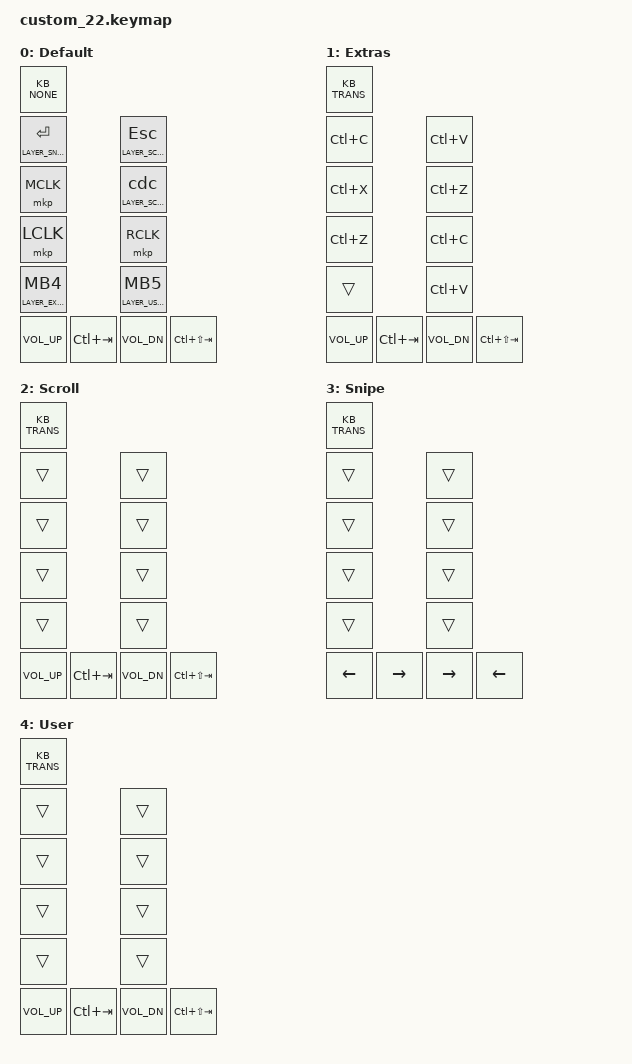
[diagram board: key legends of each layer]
/*
 * Taipo keymap for custom_22 keyboard + endgame trackball on xiao_dongle.
 *
 * Keyboard: positions 0-21 (via rolling combos)
 * Trackball buttons: positions 22-29
 * Trackball encoders: positions 30-33
 *
 * Trackball layers:
 *   0 - Default: mouse buttons, hold-tap for layers
 *   1 - Extras: copy/paste shortcuts
 *   2 - Scroll: trackball becomes scroll wheel
 *   3 - Snipe: slow precision pointer
 *   4 - User: customizable
 */

#include <behaviors.dtsi>
#include <input/processors.dtsi>
#include <dt-bindings/zmk/bt.h>
#include <dt-bindings/zmk/keys.h>
#include <dt-bindings/zmk/outputs.h>
#include <dt-bindings/zmk/pointing.h>
#include <dt-bindings/zmk/matrix_transform.h>
#include <dt-bindings/zmk/input_transform.h>

// CONFIG
#define COMBO_TIMEOUT 200
#define COMBO_LAYERS 0 1 2 3 4
#define STICKY_TIMEOUT 500

// TRACKBALL LAYERS
#define LAYER_DEFAULT      0
#define LAYER_EXTRAS       1
#define LAYER_SCROLL       2
#define LAYER_SNIPE        3
#define LAYER_USER         4

// INPUT PROCESSOR TUNING
#define TWIST_MULTIPLIER   1
#define TWIST_DIVISOR      10
#define SCROLL_MULTIPLIER  1
#define SCROLL_DIVISOR     3
#define SNIPE_MULTIPLIER   1
#define SNIPE_DIVISOR      4

// LEFT SIDE (col 0-10, no offset)
#define TLI 3
#define TLM 2
#define TLR 1
#define TLP 0
#define BLI 11
#define BLM 10
#define BLR 9
#define BLP 8
#define LOT 16
#define LIT 17

// RIGHT SIDE (col 0-10, col-offset=11 -> positions 11-21)
#define TRI 4
#define TRM 5
#define TRR 6
#define TRP 7
#define BRI 12
#define BRM 13
#define BRR 14
#define BRP 15
#define ROT 21
#define RIT 20

// Shorthand for 22 keyboard &none entries (default layer)
#define KB_NONE \
    &none &none &none &none  &none &none &none &none \
    &none &none &none &none  &none &none &none &none \
          &none &none &none  &none &none &none

// Shorthand for 22 keyboard &trans entries (non-default layers)
#define KB_TRANS \
    &trans &trans &trans &trans  &trans &trans &trans &trans \
    &trans &trans &trans &trans  &trans &trans &trans &trans \
           &trans &trans &trans  &trans &trans &trans

&sk {
    release-after-ms = <STICKY_TIMEOUT>;
    quick-release;
};

/*
 * Combined transform: keyboard 22 keys + trackball 12 keys = 34 positions.
 * Overrides the shield's 11-position transform.
 */
&default_transform {
    columns = <34>;
    map = <
        /* Keyboard positions 0-21 */
        RC(0,0)  RC(0,1)  RC(0,2)  RC(0,3)   RC(0,14)  RC(0,13)  RC(0,12)  RC(0,11)
        RC(0,4)  RC(0,5)  RC(0,6)  RC(0,7)   RC(0,18)  RC(0,17)  RC(0,16)  RC(0,15)
                 RC(0,8)  RC(0,9)  RC(0,10)  RC(0,21)  RC(0,20)  RC(0,19)
        /* Trackball positions 22-33 */
        RC(0,22) RC(0,23) RC(0,24) RC(0,25)  RC(0,26)  RC(0,27)
        RC(0,28) RC(0,29) RC(0,30) RC(0,31)  RC(0,32)  RC(0,33)
    >;
};

/ {
  /* Trackball behaviors */
  behaviors {
    ltm: layer-tap-momentary {
      compatible = "zmk,behavior-hold-tap";
      #binding-cells = <2>;
      flavor = "tap-preferred";
      tapping-term-ms = <200>;
      hold-while-undecided;
      bindings = <&mo>, <&mkp>;
    };

    ltmkp: layer-tap-momentary-key-press {
      compatible = "zmk,behavior-hold-tap";
      #binding-cells = <2>;
      flavor = "tap-preferred";
      tapping-term-ms = <200>;
      hold-while-undecided;
      bindings = <&mo>, <&kp>;
    };

    cdch: click-double-click-hold {
      compatible = "zmk,behavior-hold-tap";
      #binding-cells = <2>;
      flavor = "tap-preferred";
      tapping-term-ms = <325>;
      bindings = <&mo>, <&cdc>;
    };

    cdc: click-double-click {
      compatible = "zmk,behavior-tap-dance";
      #binding-cells = <0>;
      tapping-term-ms = <300>;
      bindings = <&kp LC(C)>, <&kp LC(V)>;
    };
  };

  rolling_combos {
    compatible = "zmk,rolling-combos";
    #include "taipo.dtsi"
  };

  keymap {
    compatible = "zmk,keymap";

    default_layer {
      display-name = "Default";
      sensor-bindings = <&inc_dec_kp C_VOL_UP C_VOL_DN &inc_dec_kp C_VOL_UP C_VOL_DN>;
      bindings = <
        KB_NONE
        /* Trackball buttons 22-29 */
        &ltmkp LAYER_SNIPE ENTER  &ltmkp LAYER_SCROLL ESC
        &mkp MCLK                 &cdch LAYER_SCROLL 0
        &mkp LCLK                 &mkp RCLK
        &ltm LAYER_EXTRAS MB4     &ltm LAYER_USER MB5
        /* Trackball encoders 30-33 */
        &kp C_VOL_UP  &kp LC(TAB)  &kp C_VOL_DN  &kp LC(LS(TAB))
      >;
    };

    extras_layer {
      display-name = "Extras";
      sensor-bindings = <&inc_dec_kp C_VOL_UP C_VOL_DN &inc_dec_kp C_VOL_UP C_VOL_DN>;
      bindings = <
        KB_TRANS
        &kp LC(C)   &kp LC(V)
        &kp LC(X)   &kp LC(Z)
        &kp LC(Z)   &kp LC(C)
        &trans       &kp LC(V)
        &kp C_VOL_UP  &kp LC(TAB)  &kp C_VOL_DN  &kp LC(LS(TAB))
      >;
    };

    scroll_layer {
      display-name = "Scroll";
      sensor-bindings = <&inc_dec_kp C_VOL_UP C_VOL_DN &inc_dec_kp C_VOL_UP C_VOL_DN>;
      bindings = <
        KB_TRANS
        &trans  &trans
        &trans  &trans
        &trans  &trans
        &trans  &trans
        &kp C_VOL_UP  &kp LC(TAB)  &kp C_VOL_DN  &kp LC(LS(TAB))
      >;
    };

    snipe_layer {
      display-name = "Snipe";
      sensor-bindings = <&inc_dec_kp C_VOL_UP C_VOL_DN &inc_dec_kp C_VOL_UP C_VOL_DN>;
      bindings = <
        KB_TRANS
        &trans  &trans
        &trans  &trans
        &trans  &trans
        &trans  &trans
        &kp LEFT  &kp RIGHT  &kp RIGHT  &kp LEFT
      >;
    };

    user_layer {
      display-name = "User";
      sensor-bindings = <&inc_dec_kp C_VOL_UP C_VOL_DN &inc_dec_kp C_VOL_UP C_VOL_DN>;
      bindings = <
        KB_TRANS
        &trans  &trans
        &trans  &trans
        &trans  &trans
        &trans  &trans
        &kp C_VOL_UP  &kp LC(TAB)  &kp C_VOL_DN  &kp LC(LS(TAB))
      >;
    };
  };

  /*
   * Trackball input processor overrides per layer (runs on central).
   * Heavy processing (acceleration, rotation, mixing) already happened
   * on the trackball peripheral. The central only applies layer-specific
   * overrides for scroll and snipe modes.
   */
  trackball_listener {
    scroll {
      layers = <LAYER_SCROLL>;
      input-processors = <&zip_xy_scaler SCROLL_MULTIPLIER SCROLL_DIVISOR>,
                         <&zip_xy_to_scroll_mapper>,
                         <&zip_scroll_transform INPUT_TRANSFORM_Y_INVERT>;
    };

    snipe {
      layers = <LAYER_SNIPE>;
      input-processors = <&zip_xy_scaler SNIPE_MULTIPLIER SNIPE_DIVISOR>;
    };
  };
};
